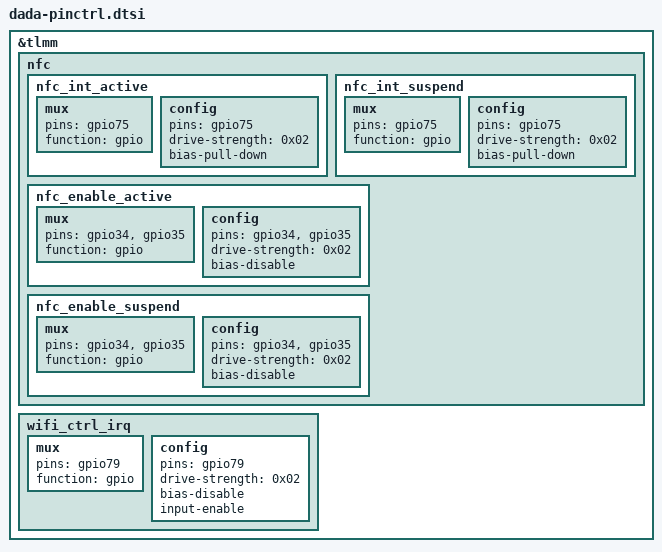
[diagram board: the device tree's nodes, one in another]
// SPDX-License-Identifier: BSD-3-Clause
/*
 * Copyright (c) 2023-2024 Qualcomm Innovation Center, Inc. All rights reserved.
 * Copyright (c) 2025 The LineageOS Project
 */

&tlmm {
	nfc {

		nfc_int_active: nfc_int_active {

			mux {
				pins = "gpio75";
				function = "gpio";
			};

			config {
				pins = "gpio75";
				drive-strength = <0x02>;
				bias-pull-down;
			};
		};

		nfc_int_suspend: nfc_int_suspend {

			mux {
				pins = "gpio75";
				function = "gpio";
			};

			config {
				pins = "gpio75";
				drive-strength = <0x02>;
				bias-pull-down;
			};
		};

		nfc_enable_active: nfc_enable_active {

			mux {
				pins = "gpio34", "gpio35";
				function = "gpio";
			};

			config {
				pins = "gpio34", "gpio35";
				drive-strength = <0x02>;
				bias-disable;
			};
		};

		nfc_enable_suspend: nfc_enable_suspend {

			mux {
				pins = "gpio34", "gpio35";
				function = "gpio";
			};

			config {
				pins = "gpio34", "gpio35";
				drive-strength = <0x02>;
				bias-disable;
			};
		};
	};

	wifi_ctrl_irq: wifi_ctrl_irq {

		mux {
			pins = "gpio79";
			function = "gpio";
		};

		config {
			pins = "gpio79";
			drive-strength = <0x02>;
			bias-disable;
			input-enable;
		};
	};
};
